# RN831X_RN861X_MCU register map
File version: v0.0.1
CPU: RN831X_RN861X_MCU r1p0, little endian, MPU, no FPU
Registers are 32-bit, read-write, reset 0x0 unless marked. A register's access mark holds for its fields unless they carry their own. Offsets are from the block's base; [hi:lo] are bit positions; {n}, {i} and the like mark numbered series; 'fields as' and 'values as' point back to an identical list.

## SYSTEM_CORE0 — SYSTEM Module core0
Base 0x20080000
0x00 SYS_PSW1 access not given — Public Password Register
  [7:0] SYS_PSW1 — When SYS_PSW1 = 8'h82, public registers are writable.
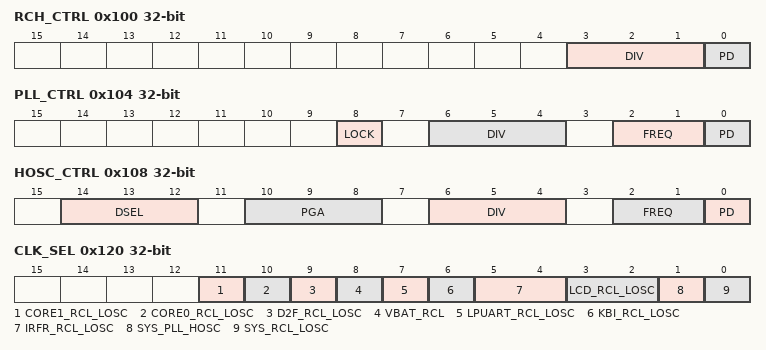
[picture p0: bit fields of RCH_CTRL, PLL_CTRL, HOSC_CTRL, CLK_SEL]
0x100 RCH_CTRL — RCH Control Register
  [3:1] DIV — RCH source clock division selection
    0=Divide by 1; 1=Divide by 2; 2=Divide by 4; 3=Divide by 8; 4=Divide by 16; 5=Divide by 32 (default)
  [0] PD — Internal RCH enable bit, main frequency is 58.9824MHz
0x104 PLL_CTRL access per field — PLL Control Register
  [8] LOCK ro — PLL lock status
  [6:4] DIV rw — PLL source clock division selection
    0=Divide by 1; 1=Divide by 2; 2=Divide by 4; 3=Divide by 8; 4=Divide by 16
  [2:1] FREQ rw — PLL output frequency selection
    0=7M3728 (PLL output frequency selection is 7.3728MHz); 1=14M7456 (PLL output frequency selection is 14.7456MHz); 2=29M4912 (PLL output frequency selection is 29.4912MHz); 3=58M9824 (PLL output frequency selection is 58.9824MHz)
  [0] PD rw — PLL module enable bit
0x108 HOSC_CTRL — HOSC Control Register
  [14:12] DSEL — HOSC analog filter time configuration
    0=25_5NS (External high-frequency crystal is 7.3728MHz); 1=10_5NS (External high-frequency crystal is 14.7456MHz); 2=5NS (External high-frequency crystal is 29.4912MHz); 4=NONE (HOSC clock does not use analog filtering)
  [10:8] PGA — HOSC gain selection
    0=1X_0_8MS (1x transconductance gain, 928uA current, 0.8mS); 1=2X_2_4MS (2x transconductance gain, 1856uA current, 2.4mS); 2=4X_3_2MS (4x transconductance gain, 3712uA current, 3.2mS); 3=8X_5_6MS (8x transconductance gain, 7424uA current, 5.6mS); 4=1X_1_2MS (1x transconductance gain, enhanced gain, 1.2mS); 5=2X_1_6MS (2x transconductance gain, enhanced gain, 1.6mS); 6=4X_4_8MS (4x transconductance gain, enhanced gain, 4.8mS); 7=8X_6_4MS (8x transconductance gain, enhanced gain, 6.4mS)
  [6:4] DIV — HOSC source clock division selection
    values as PLL_CTRL.DIV
  [2:1] FREQ — External high-frequency crystal selection
    0=7M3728 (External high-frequency crystal is 7.3728MHz); 1=14M7456 (External high-frequency crystal is 14.7456MHz); 2=29M4912 (External high-frequency crystal is 29.4912MHz)
  [0] PD — External High-Frequency Oscillator enable bit
0x10C RCL307K_CTRL access not given — RCL307K Control Register
  [7:0] PD — RCL307K Enable Switch
0x120 CLK_SEL — Clock Selection Register
  [11] CORE1_RCL_LOSC — CORE1 Low-Frequency Clock Source Selection
  [10] CORE0_RCL_LOSC — CORE0 Low-Frequency Clock Source Selection
  [9] D2F_RCL_LOSC — D2F Low-Frequency Clock Source Selection
  [8] VBAT_RCL — RCL32K clock channel switch to VBAT domain
  [7] LPUART_RCL_LOSC — LPUART Low-Frequency Clock Source Selection
  [6] KBI_RCL_LOSC — KBI Clock Source selection
  [5:4] IRFR_RCL_LOSC — IRFR Clock Source selection
    0=LOSC (IRFR selects LOSC external low-frequency crystal as clock source); 1=RCL32K (IRFR selects RCL32k internal low-frequency crystal as clock source); 2=RCL307K (IRFR selects RCL307k internal low-frequency crystal as clock source)
  [3:2] LCD_RCL_LOSC — LCD Clock Source selection
    0=LOSC (LCD selects LOSC external low-frequency crystal as clock source); 1=RCL32K (LCD selects RCL32k internal low-frequency crystal as clock source); 2=RCL307K (LCD selects RCL307k internal low-frequency crystal as clock source (Not available))
  [1] SYS_PLL_HOSC — High-frequency operation system main clock selection
  [0] SYS_RCL_LOSC — Low-frequency operation system main clock selection
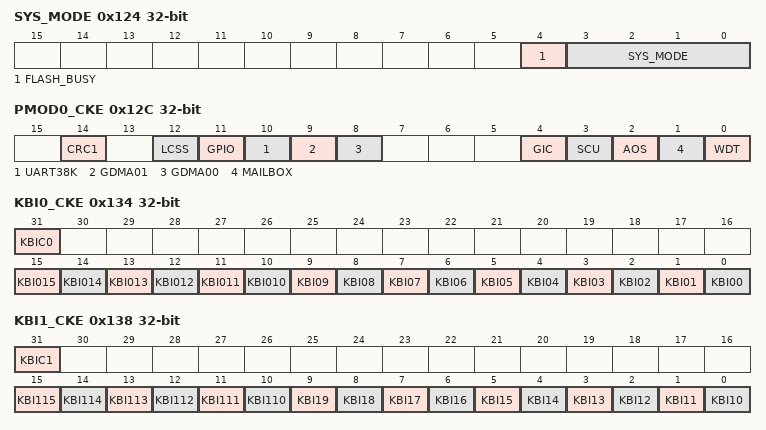
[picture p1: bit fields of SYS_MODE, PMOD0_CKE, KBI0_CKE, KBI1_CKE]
0x124 SYS_MODE access per field — System Mode Register
  [4] FLASH_BUSY ro — Flash busy status
  [3:0] SYS_MODE rw — set to enter HCM/RC/LCM mode
    4=HCM (Write D, set to enter high-frequency mode HCM, read value 4'b0100); 2=RCM (Write E, set to enter RC mode RCM, read value 4'b0010); 1=LCM (Write F, set to enter 32.768KHz mode LCM, read value 4'b0001)
0x128 CORE_DIV — CORE Clock Division Register
  [3:0] CORE1_CORE0_DIV — CORE0/CORE1 main clock division configuration
    0=CORE1_NONE_CORE0_NONE (CORE1 no division, CORE0 no division); 1=CORE1_NONE_CORE0_2 (CORE1 no division, CORE0 divide by 2); 2=CORE1_NONE_CORE0_4 (CORE1 no division, CORE0 divide by 4); 3=CORE1_NONE_CORE0_8 (CORE1 no division, CORE0 divide by 8); 5=CORE1_2_CORE0_2 (CORE1 divide by 2, CORE0 divide by 2); 6=CORE1_2_CORE0_4 (CORE1 divide by 2, CORE0 divide by 4); 7=CORE1_2_CORE0_8 (CORE1 divide by 2, CORE0 divide by 8); 10=CORE1_4_CORE0_4 (CORE1 divide by 4, CORE0 divide by 4); 11=CORE1_4_CORE0_8 (CORE1 divide by 4, CORE0 divide by 8); 15=CORE1_8_CORE0_8 (CORE1 divide by 8, CORE0 divide by 8)
0x12C PMOD0_CKE — Private Module Clock Enable Register
  [14] CRC1 — CRC1 module clock enable
  [12] LCSS — LCSS module enable
  [11] GPIO — GPIO module enable
  [10] UART38K — UART38K module clock enable
  [9] GDMA01 — GDMA01 module clock enable
  [8] GDMA00 — GDMA00 module clock enable
  [4] GIC — CORE0_GIC module clock enable
  [3] SCU — CORE0_SCU module clock enable
  [2] AOS — CORE0_AOS module clock enable
  [1] MAILBOX — CORE0_MAILBOX module clock enable
  [0] WDT — CORE0_WDT APB clock enable
0x130 CORE1_CKE access not given — Core1 Clock Enable Register
  [15:0] CORE1_CKE — Disable/enable for CORE1 system
0x134 KBI0_CKE — KBI0 Clock Enable Register
  [31] KBIC0 — KBIC0 APB module clock enable
  [n] KBI{n:03} (n=10..15) — KBI{n:03} module clock enable
  [n] KBI{n:02} (n=0..9) — KBI{n:02} module clock enable
0x138 KBI1_CKE — KBI1 Clock Enable Register
  [31] KBIC1 — KBIC1 APB module clock enable
  [n-100] KBI{n} (n=110..115) — KBI{n} module clock enable
  [n-10] KBI{n} (n=10..19) — KBI{n-10:02} module clock enable
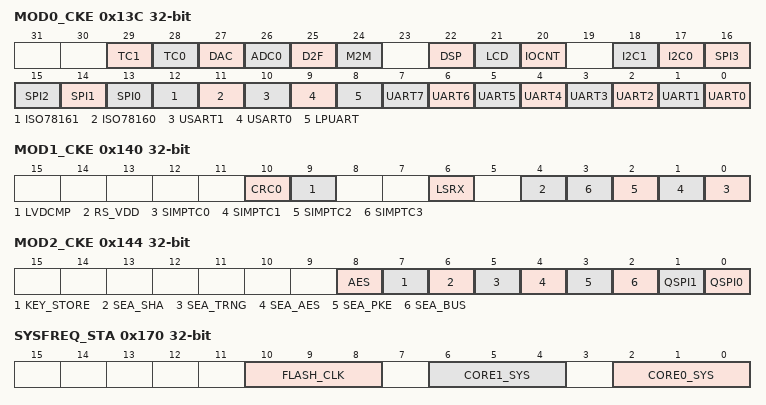
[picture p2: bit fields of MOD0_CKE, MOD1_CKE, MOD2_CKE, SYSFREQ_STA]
0x13C MOD0_CKE — Module Clock Enable Register 0
  [29] TC1 — TC1 module clock enable
  [28] TC0 — TC0 module clock enable
  [27] DAC — DAC module clock enable
  [26] ADC0 — ADC0 module clock enable
  [25] D2F — D2F module clock enable
  [24] M2M — M2M module clock enable
  [22] DSP — DSP module clock enable
  [21] LCD — LCD module clock enable
  [20] IOCNT — IOCNT module clock enable
  [18] I2C1 — I2C1 module clock enable
  [17] I2C0 — I2C0 module clock enable
  [n+13] SPI{n} (n=0..3) — SPI{n} module clock enable
  [12] ISO78161 — ISO7816_1 module clock enable
  [11] ISO78160 — ISO7816_0 module clock enable
  [10] USART1 — USART1 module clock enable
  [9] USART0 — USART0 module clock enable
  [8] LPUART — LPUART module clock enable
  [n] UART{n} (n=0..7) — UART{n} module clock enable
0x140 MOD1_CKE — Module Clock Enable Register 1
  [10] CRC0 — CRC0 Module Clock Enable
  [9] LVDCMP — LVDCMP Module Clock Enable
  [6] LSRX — LSRX Module Clock Enable
  [4] RS_VDD — RS_VDD Module Clock Enable
  [n] SIMPTC{n} (n=0..3) — SIMP_TC{n} Module Clock Enable
0x144 MOD2_CKE — Module Clock Enable Register 2
  [8] AES — AES Module Clock Enable
  [7] KEY_STORE — KEY_STORE Module Clock Enable
  [6] SEA_SHA — SEA_SHA Module Clock Enable
  [5] SEA_TRNG — SEA_TRNG Module Clock Enable
  [4] SEA_AES — SEA_AES Module Clock Enable
  [3] SEA_PKE — SEA_PKE Module Clock Enable
  [2] SEA_BUS — SEA_BUS Module Clock Enable
  [1] QSPI1 — QSPI1 Module Clock Enable
  [0] QSPI0 — QSPI0 Module Clock Enable
0x170 SYSFREQ_STA ro — System Clock Frequency Indication Register
  [10:8] FLASH_CLK — Flash System Frequency Indication
    0=32K768 (Current Flash clock is 32.768KHz); 1=1M8432 (Current Flash clock is 1.8432MHz); 2=3M6864 (Current Flash clock is 3.6864MHz); 3=7M3728 (Current Flash clock is 7.3728MHz); 4=14M7456 (Current Flash clock is 14.7456MHz); 5=29M4912 (Current Flash clock is 29.4912MHz); 6=58M9824 (Current Flash clock is 58.9824MHz); 7=OVERRANGE (Current Flash configuration exceeds allowed operating frequency range)
  [6:4] CORE1_SYS — CORE1 System Main Clock Frequency Indication
    0=32K768 (Current system main clock is 32.768KHz); 1=1M8432 (Current system main clock is 1.8432MHz); 2=3M6864 (Current system main clock is 3.6864MHz); 3=7M3728 (Current system main clock is 7.3728MHz); 4=14M7456 (Current system main clock is 14.7456MHz); 5=29M4912 (Current system main clock is 29.4912MHz); 6=58M9824 (Current system main clock is 58.9824MHz); 7=OVERRANGE (Current system main clock configuration exceeds allowed operating frequency range)
  [2:0] CORE0_SYS — CORE0 System Main Clock Frequency Indication
    0=32K768 (Current system main clock is 32.768KHz); 1=1M8432 (Current system main clock is 1.8432MHz); 2=3M6864 (Current system main clock is 3.6864MHz); 3=7M3728 (Current system main clock is 7.3728MHz); 4=14M7456 (Current system main clock is 14.7456MHz); 5=29M4912 (Current system main clock is 29.4912MHz); 7=OVERRANGE (Current system main clock configuration exceeds allowed operating frequency range)
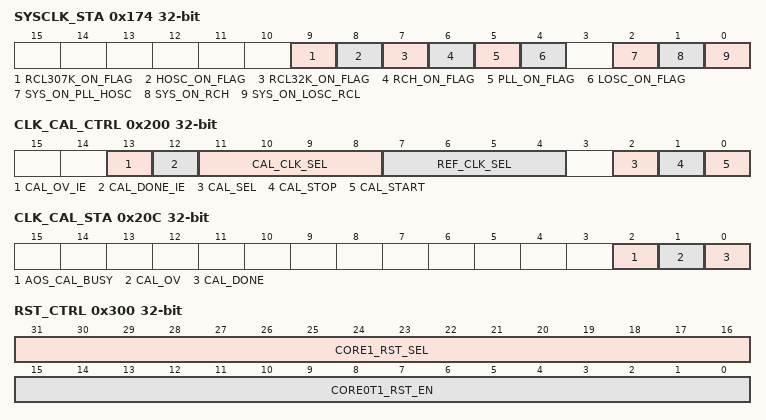
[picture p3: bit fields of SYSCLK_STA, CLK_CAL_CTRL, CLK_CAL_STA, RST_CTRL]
0x174 SYSCLK_STA ro — System Clock Status Register
  [9] RCL307K_ON_FLAG — RCL307K Clock Enable Flag
  [8] HOSC_ON_FLAG — HOSC Clock Enable Flag
  [7] RCL32K_ON_FLAG — RCL32K Clock Enable Flag
  [6] RCH_ON_FLAG — RCH Clock Enable Flag
  [5] PLL_ON_FLAG — PLL Clock Enable Flag
  [4] LOSC_ON_FLAG — LOSC Clock Enable Flag
  [2] SYS_ON_PLL_HOSC — Set to 1 when the system runs on external high frequency (HOSC) or internal PLL clock
  [1] SYS_ON_RCH — Set to 1 when the system runs on internal high frequency clock (RCH)
  [0] SYS_ON_LOSC_RCL — Set to 1 when the system runs on external low frequency (LOSC) or internal RCL32K clock
0x200 CLK_CAL_CTRL — Clock Calibration Control Register
  [13] CAL_OV_IE — Calibrated Clock Counter Overflow Flag Interrupt Enable
  [12] CAL_DONE_IE — Clock Calibration Complete Flag Interrupt Enable
  [11:8] CAL_CLK_SEL — Clock Under Test Source Selection
    0=LOSC (Select LOSC as clock under test); 1=RCL32K (Select RCL_32K as clock under test); 2=HOSC (Select HOSC as clock under test); 3=RCHVCC (Select RCH_VCC as clock under test); 4=PLL (Select PLL as clock under test); 5=RCHVBAT (Select RCH_VBAT as clock under test); 6=RCL307K (Select RCL_307K as clock under test)
  [7:4] REF_CLK_SEL — Reference Clock Source Selection
    0=LOSC (Select LOSC as reference clock); 1=RCL32K (Select RCL_32K as reference clock); 2=HOSC (Select HOSC as reference clock); 3=RCHVCC (Select RCH_VCC as reference clock); 4=PLL (Select PLL as reference clock); 5=RCHVBAT (Select RCH_VBAT as reference clock); 6=RCL307K (Select RCL_307K as reference clock)
  [2] CAL_SEL — Clock Calibration Source Selection
  [1] CAL_STOP — Clock Calibration Stop Bit
  [0] CAL_START — Clock Calibration Start Bit
0x204 CLK_REF_CNT access not given — Clock Reference Count Register
  [23:0] REF_CLK_CNT — Reference Clock Count Value
0x208 CLK_CAL_CNT access not given — Clock Target Count Register
  [23:0] CAL_CLK_CNT — Count value returned by the clock under calibration
0x20C CLK_CAL_STA access per field — Clock Calibration Status Register
  [2] AOS_CAL_BUSY ro — AOS triggers the calibration busy flag
  [1] CAL_OV rw — Calibrated Clock Counter Overflow Flag
  [0] CAL_DONE rw — Clock Calibration Complete Flag
0x300 RST_CTRL — Reset Control Register
  [31:16] CORE1_RST_SEL — CORE1 WDT and Soft Reset Target Selection
  [15:0] CORE0T1_RST_EN — CORE0 Reset CORE1 Enable
0x304 RST_STOP_CTRL access not given — Reset State Stop Control Register
  [15:0] CORE1_STOP — CORE1 STOP ON RESET Selection
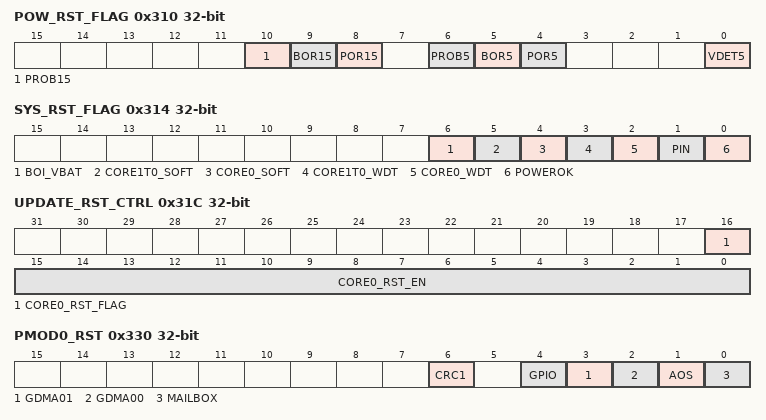
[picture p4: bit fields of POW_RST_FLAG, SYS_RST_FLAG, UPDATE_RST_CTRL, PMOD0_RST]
0x310 POW_RST_FLAG — Power Reset Source Flag Register
  [10] PROB15 write-1-clears — PROB15 Reset Flag
  [9] BOR15 write-1-clears — BOR15 Reset Flag
  [8] POR15 write-1-clears — POR15 Reset Flag
  [6] PROB5 write-1-clears — PROB5 Reset Flag
  [5] BOR5 write-1-clears — BOR5 Reset Flag
  [4] POR5 write-1-clears — POR5 Reset Flag
  [0] VDET5 write-1-clears — VDET5 Reset Flag
0x314 SYS_RST_FLAG — System Reset Flag Register
  [6] BOI_VBAT write-1-clears — VBAT BOI Power-Down Reset Occurred
  [5] CORE1T0_SOFT write-1-clears — CORE1T 0 Software Reset Flag
  [4] CORE0_SOFT write-1-clears — CORE0 Software Reset Flag
  [3] CORE1T0_WDT write-1-clears — CORE1T0 WDT Reset Flag
  [2] CORE0_WDT write-1-clears — CORE0 WDT Reset Flag
  [1] PIN write-1-clears — External Pin Reset Flag
  [0] POWEROK write-1-clears — Power Reset Flag
0x318 BOI_RST_CTRL access not given — BOI_VBAT Reset Control Register
  [6] BOI_VBAT_RST_IE — BOI_VBAT_RST Interrupt Enable Bit
0x31C UPDATE_RST_CTRL — Update Reset Control Register
  [16] CORE0_RST_FLAG write-1-clears — CORE0 Update Reset Flag
  [15:0] CORE0_RST_EN — CORE0 Update Reset Enable
0x330 PMOD0_RST — CORE0 Private Module Reset Register
  [6] CRC1 — Software reset CRC1 module
  [4] GPIO — Software reset GPIO module
  [3] GDMA01 — Software reset GDMA01 module
  [2] GDMA00 — Software reset GDMA00 module
  [1] AOS — Software reset AOS module
  [0] MAILBOX — Software reset MAILBOX module
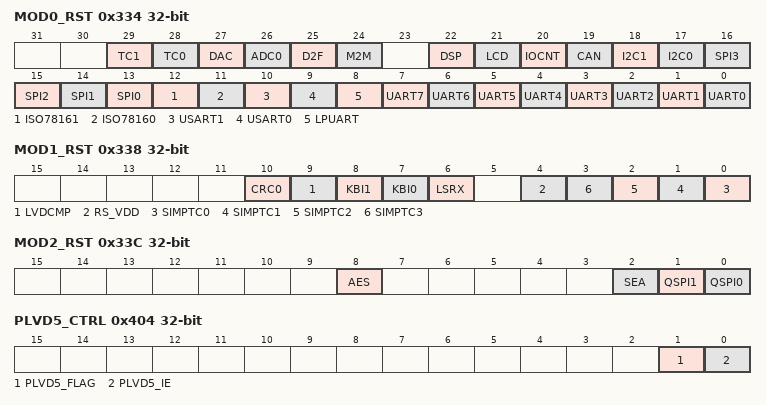
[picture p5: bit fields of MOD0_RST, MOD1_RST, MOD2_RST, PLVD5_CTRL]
0x334 MOD0_RST — Assignable Module 0 Reset Register
  [29] TC1 — Software reset TC1 module
  [28] TC0 — Software reset TC0 module
  [27] DAC — Software reset DAC module
  [26] ADC0 — Software reset ADC0 module
  [25] D2F — Software reset D2F module
  [24] M2M — Software reset M2M module
  [22] DSP — Software reset DSP module
  [21] LCD — Software reset LCD module
  [20] IOCNT — Software reset IOCNT module
  [19] CAN — Software reset CAN module
  [18] I2C1 — Software reset I2C1 module
  [17] I2C0 — Software reset I2C0 module
  [n+13] SPI{n} (n=0..3) — Software reset SPI{n} module
  [12] ISO78161 — Software reset ISO78161 module
  [11] ISO78160 — Software reset ISO78160 module
  [10] USART1 — Software reset USART1 module
  [9] USART0 — Software reset USART0 module
  [8] LPUART — Software reset LPUART module
  [n] UART{n} (n=0..7) — Software reset UART{n} module
0x338 MOD1_RST — Assignable Module 1 Reset Register
  [10] CRC0 — Software reset CRC0 module
  [9] LVDCMP — Software reset LVDCMP module
  [8] KBI1 — Software reset KBI1 module
  [7] KBI0 — Software reset KBI0 module
  [6] LSRX — Software reset LSRX module
  [4] RS_VDD — Software reset RS_VDD module
  [n] SIMPTC{n} (n=0..3) — Software reset SIMP_TC{n} module
0x33C MOD2_RST — Assignable Module 2 Reset Register
  [8] AES — Software reset AES module
  [2] SEA — Software reset SEA module
  [1] QSPI1 — Software reset QSPI1 module
  [0] QSPI0 — Software reset QSPI0 module
0x400 BOR5_CTRL access not given — BOR5 Control Register
  [15:0] BOR5_SEL — BOR5 Threshold Selection Signal, Power-up threshold / Power-down threshold
0x404 PLVD5_CTRL — PLVD5 Control Register
  [1] PLVD5_FLAG write-1-clears — PLVD5 Low Voltage Event Occurred
  [0] PLVD5_IE — PLVD5 Interrupt Enable
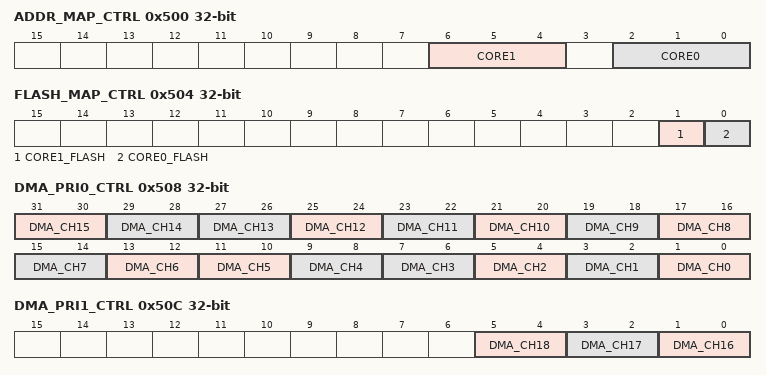
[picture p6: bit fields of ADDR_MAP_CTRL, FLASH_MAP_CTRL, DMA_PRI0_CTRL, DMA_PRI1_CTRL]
0x500 ADDR_MAP_CTRL access per field — Address Mapping Control Register
  [6:4] CORE1 ro — Core1 Address ReMapping
    0=CORE1 FLASH mapped to address 0x8000_0000; 1=CORE1 FLASH mapped to address 0x9000_0000; 2=CORE1 FLASH mapped to address 0x8100_0000
  [2:0] CORE0 rw — Core0 Address ReMapping
    0=CORE0 FLASH mapped to address 0x0020_0000; 1=CORE0 FLASH mapped to address 0x0000_0000; 2=CORE0 FLASH mapped to address 0x1020_0000
0x504 FLASH_MAP_CTRL access per field — FLASH Mapping Control Register
  [1] CORE1_FLASH ro — Core1 Flash Address Mapping
  [0] CORE0_FLASH rw — Core0 Flash Address Mapping
0x508 DMA_PRI0_CTRL — DMA Access SRAM Priority Configuration Register 0
  [31:30] DMA_CH15 — Channel 15: TC0_PWM channel access SRAM priority configuration.
  [29:28] DMA_CH14 — Channel 14: CAN channel access SRAM priority configuration.
  [2n+1:2n] DMA_CH{n} (n=6..13) — Channel {n}: UART{n-6} channel access SRAM priority configuration.
  [11:10] DMA_CH5 — Channel 5: DAC channel access SRAM priority configuration.
  [9:8] DMA_CH4 — Channel 4: SARADC channel access SRAM priority configuration.
  [2n+1:2n] DMA_CH{n} (n=0..3) — Channel {n}: SPI{n} channel access SRAM priority configuration.
0x50C DMA_PRI1_CTRL — DMA Access SRAM Priority Configuration Register 1
  [5:4] DMA_CH18 — Channel 18: M2M channel access SRAM priority configuration.
  [3:2] DMA_CH17 — Channel 17: AES channel access SRAM priority configuration.
  [1:0] DMA_CH16 — Channel 16: TC1_PWM channel access SRAM priority configuration.
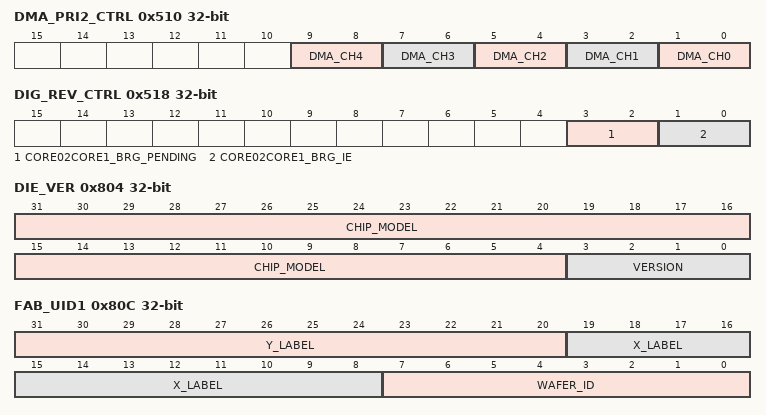
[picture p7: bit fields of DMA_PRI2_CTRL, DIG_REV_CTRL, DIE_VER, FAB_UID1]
0x510 DMA_PRI2_CTRL — DMA Access SRAM Priority Configuration Register 2
  [9:8] DMA_CH4 — Channel 4: CORE0/CORE1 channel access SRAM priority configuration.
  [7:6] DMA_CH3 — Channel 3: DSP channel access SRAM priority configuration.
  [5:4] DMA_CH2 — Channel 2: General DMA write channel (MDMA0x_WR/MDMA1x_WR) access SRAM priority configuration.
  [3:2] DMA_CH1 — Channel 1: General DMA read channel (MDMA0x_RD/MDMA1x_RD) access SRAM priority configuration.
  [1:0] DMA_CH0 — Channel 0: First level arbitration result channel access SRAM priority configuration.
0x514 IRFR_CTRL access not given — Infrared Control Register
  [7:0] INFRARED_CYCLE — Infrared clock division factor in HCMM and RCMM modes, based on 7.3728MHZ
0x518 DIG_REV_CTRL — Reserved Digital Control Register
  [3:2] CORE02CORE1_BRG_PENDING write-1-clears — CORE02CORE1 Bridge Illegal Access Flag
  [1:0] CORE02CORE1_BRG_IE — CORE02CORE1 Bridge Illegal Access Interrupt Enable
0x800 CHIP_ID access not given
  [15:0] CHIP_ID — CHIP_ID: C248
0x804 DIE_VER ro — Chip Version Register
  [31:4] CHIP_MODEL — Chip Model: A9701C, Encoded in ASCII
  [3:0] VERSION — Version Number
0x808 FAB_UID0 access not given — Chip Unique ID 0 Register
  [31:0] LOT_NUM — This register is configured by the bootloader
0x80C FAB_UID1 ro — Chip Unique ID 1 Register
  [31:20] Y_LABEL — DIE Y-coordinate
  [19:8] X_LABEL — DIE X-coordinate
  [7:0] WAFER_ID — the wafer WAFER ID information
